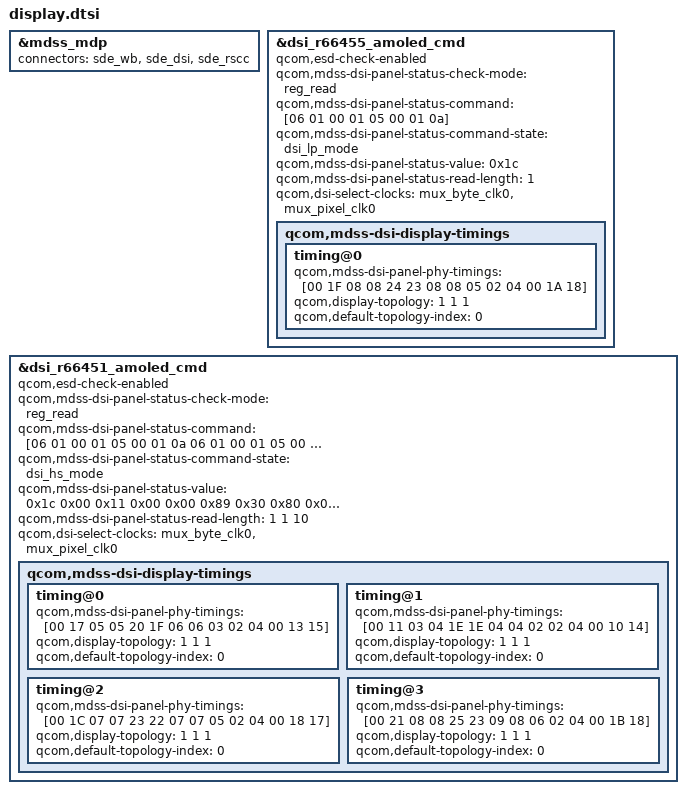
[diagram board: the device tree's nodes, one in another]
/*
 * nubia overwrite dts
 */

#include "dsi_r66455_1080_2340_amoled_cmd.dtsi"
#include "dsi_r66451_1080_2340_amoled_cmd.dtsi"

&mdss_mdp {
	connectors = <&sde_wb &sde_dsi &sde_rscc>;
};

&dsi_r66455_amoled_cmd {
	qcom,esd-check-enabled;
	qcom,mdss-dsi-panel-status-check-mode = "reg_read";
	qcom,mdss-dsi-panel-status-command = [06 01 00 01 05 00 01 0a];
	qcom,mdss-dsi-panel-status-command-state = "dsi_lp_mode";
	qcom,mdss-dsi-panel-status-value = <0x1c>;
	qcom,mdss-dsi-panel-status-read-length = <1>;
	//qcom,dsi-supported-dfps-list = <60 55 48>;
	//qcom,mdss-dsi-pan-enable-dynamic-fps;
	//qcom,mdss-dsi-pan-fps-update = "dfps_immediate_porch_mode_vfp";
	//qcom,mdss-dsi-min-refresh-rate = <48>;
	//qcom,mdss-dsi-max-refresh-rate = <60>;
	qcom,dsi-select-clocks = "mux_byte_clk0", "mux_pixel_clk0";
	qcom,mdss-dsi-display-timings {
		timing@0 {
			qcom,mdss-dsi-panel-phy-timings = [00 1F 08 08 24 23
				08 08 05 02 04 00 1A 18];
			qcom,display-topology = <1 1 1>;
			qcom,default-topology-index = <0>;
			//qcom,partial-update-enabled = "single_roi";
			//qcom,panel-roi-alignment = <720 180 180 180 1440 180>;
		};
	};
};

&dsi_r66451_amoled_cmd {
	qcom,esd-check-enabled;
	qcom,mdss-dsi-panel-status-check-mode = "reg_read";
	qcom,mdss-dsi-panel-status-command = [06 01 00 01 05 00 01 0a
		06 01 00 01 05 00 01 f9
		06 01 00 01 05 00 01 f8];
	qcom,mdss-dsi-panel-status-command-state = "dsi_hs_mode";
	qcom,mdss-dsi-panel-status-value = <0x1c 0x00 0x11 0x00 0x00 0x89 0x30 0x80 0x09 0x24 0x04 0x38>;
        qcom,mdss-dsi-panel-status-read-length = <1 1 10>;
	//qcom,dsi-supported-dfps-list = <60 55 48>;
	//qcom,mdss-dsi-pan-enable-dynamic-fps;
	//qcom,mdss-dsi-pan-fps-update = "dfps_immediate_porch_mode_vfp";
	//qcom,mdss-dsi-min-refresh-rate = <48>;
	//qcom,mdss-dsi-max-refresh-rate = <60>;
	qcom,dsi-select-clocks = "mux_byte_clk0", "mux_pixel_clk0";
	qcom,mdss-dsi-display-timings {
		timing@0 { /* 90Hz */
			qcom,mdss-dsi-panel-phy-timings = [00 17 05 05 20 1F
				06 06 03 02 04 00 13 15];
			qcom,display-topology = <1 1 1>;
			qcom,default-topology-index = <0>;
		};
		timing@1 { /* 60Hz */
			qcom,mdss-dsi-panel-phy-timings = [00 11 03 04 1E 1E
				04 04 02 02 04 00 10 14];
			qcom,display-topology = <1 1 1>;
			qcom,default-topology-index = <0>;
		};
		timing@2 { /* 120Hz */
			qcom,mdss-dsi-panel-phy-timings = [00 1C 07 07 23 22
				07 07 05 02 04 00 18 17];
			qcom,display-topology = <1 1 1>;
			qcom,default-topology-index = <0>;
		};
		timing@3 { /* 144Hz */
			qcom,mdss-dsi-panel-phy-timings = [00 21 08 08 25 23
				09 08 06 02 04 00 1B 18];
			qcom,display-topology = <1 1 1>;
			qcom,default-topology-index = <0>;
		};
	};
};
